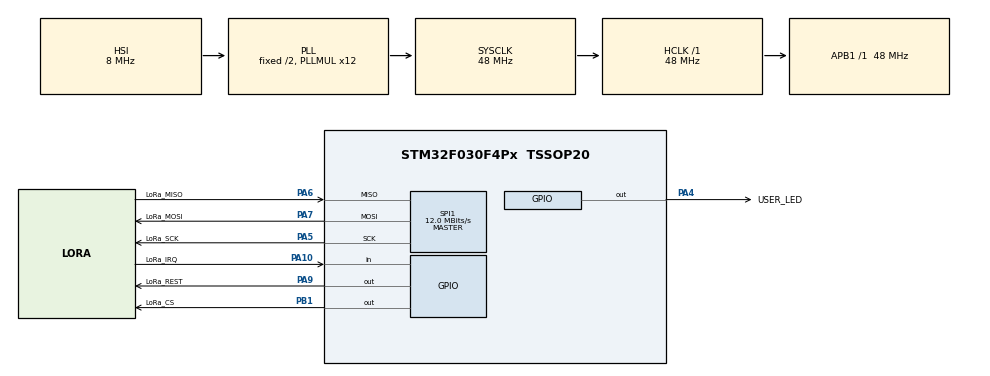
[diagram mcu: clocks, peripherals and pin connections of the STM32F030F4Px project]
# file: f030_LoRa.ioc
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Mcu.Family=STM32F0
Mcu.Name=STM32F030F4Px
Mcu.Package=TSSOP20
PA10.GPIO_Label=LoRa_IRQ
PA10.GPIO_PuPd=GPIO_PULLUP
PA10.Signal=GPIO_Input
PA4.GPIO_Label=USER_LED
PA4.Signal=GPIO_Output
PA5.GPIO_Label=LoRa_SCK
PA5.Mode=Full_Duplex_Master
PA5.Signal=SPI1_SCK
PA6.GPIO_Label=LoRa_MISO
PA6.Mode=Full_Duplex_Master
PA6.Signal=SPI1_MISO
PA7.GPIO_Label=LoRa_MOSI
PA7.Mode=Full_Duplex_Master
PA7.Signal=SPI1_MOSI
PA9.GPIO_Label=LoRa_REST
PA9.Signal=GPIO_Output
PB1.GPIO_Label=LoRa_CS
PB1.GPIO_Speed=GPIO_SPEED_FREQ_HIGH
PB1.Signal=GPIO_Output
ProjectManager.HeapSize=0x200
ProjectManager.StackSize=0x400
ProjectManager.TargetToolchain=MDK-ARM V5
RCC.AHBFreq_Value=48000000
RCC.APB1Freq_Value=48000000
RCC.APB1TimFreq_Value=48000000
RCC.HCLKFreq_Value=48000000
RCC.PLLMUL=RCC_PLL_MUL12
RCC.SYSCLKFreq_VALUE=48000000
RCC.SYSCLKSource=RCC_SYSCLKSOURCE_PLLCLK
SPI1.BaudRatePrescaler=SPI_BAUDRATEPRESCALER_4
SPI1.CalculateBaudRate=12.0 MBits/s
SPI1.DataSize=SPI_DATASIZE_8BIT
SPI1.Direction=SPI_DIRECTION_2LINES
SPI1.Mode=SPI_MODE_MASTER
SPI1.VirtualType=VM_MASTER
board=custom

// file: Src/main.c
/* USER CODE BEGIN Header */
/**
  ******************************************************************************
  * @file           : main.c
  * @brief          : Main program body
  ******************************************************************************
  * @attention
  *
  * <h2><center>&copy; Copyright (c) 2019 STMicroelectronics.
  * All rights reserved.</center></h2>
  *
  * This software component is licensed by ST under BSD 3-Clause license,
  * the "License"; You may not use this file except in compliance with the
  * License. You may obtain a copy of the License at:
  *                        opensource.org/licenses/BSD-3-Clause
  *
  ******************************************************************************
  */
/* USER CODE END Header */

#include "main.h"
#include "spi.h"
#include "gpio.h"

/* USER CODE BEGIN Includes */

#include <sx1278.h>

/* USER CODE END Includes */

void SystemClock_Config(void);

int main(void)
{

  /* MCU Configuration--------------------------------------------------------*/

  /* Reset of all peripherals, Initializes the Flash interface and the Systick. */
  HAL_Init();

  /* Configure the system clock */
  SystemClock_Config();

  /* Initialize all configured peripherals */
  MX_GPIO_Init();
  MX_SPI1_Init();
  /* USER CODE BEGIN 2 */
	LoRa_Init(433E6, 5, 0x34);
	HAL_Delay(10);
	HAL_GPIO_WritePin(USER_LED_GPIO_Port, USER_LED_Pin, GPIO_PIN_SET);
	uint8_t RxLen;
	uint8_t RxBuff[256];
  /* USER CODE END 2 */

  /* Infinite loop */
  while (1)
  {
		if(LoRa_ParsePacket(0))
		{
			RxLen = LoRa_Read(REG_RX_NB_BYTES);
			for(int i = 0; i < RxLen; i ++)
			{
				RxBuff[i] = LoRa_Read(REG_FIFO);
			}
		}
		if(RxBuff[0])
		{
			HAL_GPIO_WritePin(USER_LED_GPIO_Port, USER_LED_Pin, GPIO_PIN_RESET);
		}
		else
		{
			HAL_GPIO_WritePin(USER_LED_GPIO_Port, USER_LED_Pin, GPIO_PIN_SET);
		}

  }
}

void SystemClock_Config(void)
{
  RCC_OscInitTypeDef RCC_OscInitStruct = {0};
  RCC_ClkInitTypeDef RCC_ClkInitStruct = {0};

  /** Initializes the CPU, AHB and APB busses clocks
  */
  RCC_OscInitStruct.OscillatorType = RCC_OSCILLATORTYPE_HSI;
  RCC_OscInitStruct.HSIState = RCC_HSI_ON;
  RCC_OscInitStruct.HSICalibrationValue = RCC_HSICALIBRATION_DEFAULT;
  RCC_OscInitStruct.PLL.PLLState = RCC_PLL_ON;
  RCC_OscInitStruct.PLL.PLLSource = RCC_PLLSOURCE_HSI;
  RCC_OscInitStruct.PLL.PLLMUL = RCC_PLL_MUL12;
  RCC_OscInitStruct.PLL.PREDIV = RCC_PREDIV_DIV1;
  if (HAL_RCC_OscConfig(&RCC_OscInitStruct) != HAL_OK)
  {
    Error_Handler();
  }
  /** Initializes the CPU, AHB and APB busses clocks
  */
  RCC_ClkInitStruct.ClockType = RCC_CLOCKTYPE_HCLK|RCC_CLOCKTYPE_SYSCLK
                              |RCC_CLOCKTYPE_PCLK1;
  RCC_ClkInitStruct.SYSCLKSource = RCC_SYSCLKSOURCE_PLLCLK;
  RCC_ClkInitStruct.AHBCLKDivider = RCC_SYSCLK_DIV1;
  RCC_ClkInitStruct.APB1CLKDivider = RCC_HCLK_DIV1;

  if (HAL_RCC_ClockConfig(&RCC_ClkInitStruct, FLASH_LATENCY_1) != HAL_OK)
  {
    Error_Handler();
  }
}

void Error_Handler(void)
{
}

/************************ (C) COPYRIGHT STMicroelectronics *****END OF FILE****/
